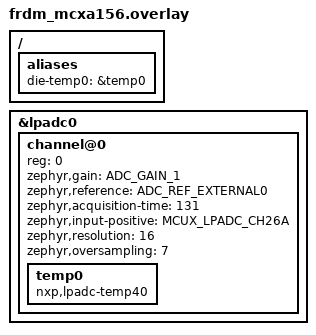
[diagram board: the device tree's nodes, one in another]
/*
 * Copyright 2025 NXP
 *
 * SPDX-License-Identifier: Apache-2.0
 */

#include <zephyr/dt-bindings/adc/mcux-lpadc.h>

/ {
	aliases {
		die-temp0 = &temp0;
	};
};

&lpadc0 {
	status = "okay";
	#address-cells = <1>;
	#size-cells = <0>;

	channel@0 {
		reg = <0>;
		zephyr,gain = "ADC_GAIN_1";
		zephyr,reference = "ADC_REF_EXTERNAL0";
		zephyr,acquisition-time = <131>;
		zephyr,input-positive = <MCUX_LPADC_CH26A>;
		zephyr,resolution = <16>;
		zephyr,oversampling = <7>;

		temp0: temp0 {
			compatible = "nxp,lpadc-temp40";
			status = "okay";
		};
	};
};
